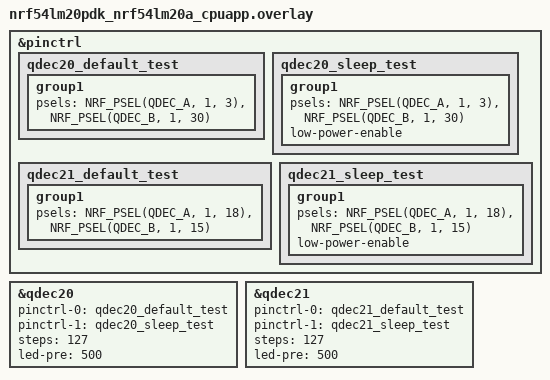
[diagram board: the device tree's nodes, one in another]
/*
 * Copyright (c) 2025 Nordic Semiconductor ASA
 *
 * SPDX-License-Identifier: LicenseRef-Nordic-5-Clause
 */

&pinctrl {
	qdec20_default_test: qdec20_default_test {
		group1 {
			psels = <NRF_PSEL(QDEC_A, 1, 3)>,
				<NRF_PSEL(QDEC_B, 1, 30)>;
		};
	};

	qdec20_sleep_test: qdec20_sleep_test {
		group1 {
			psels = <NRF_PSEL(QDEC_A, 1, 3)>,
				<NRF_PSEL(QDEC_B, 1, 30)>;
			low-power-enable;
		};
	};

	qdec21_default_test: qdec21_default_test {
		group1 {
			psels = <NRF_PSEL(QDEC_A, 1, 18)>,
				<NRF_PSEL(QDEC_B, 1, 15)>;
		};
	};

	qdec21_sleep_test: qdec21_sleep_test {
		group1 {
			psels = <NRF_PSEL(QDEC_A, 1, 18)>,
				<NRF_PSEL(QDEC_B, 1, 15)>;
			low-power-enable;
		};
	};
};

&qdec20 {
	status = "okay";
	pinctrl-0 = <&qdec20_default_test>;
	pinctrl-1 = <&qdec20_sleep_test>;
	pinctrl-names = "default", "sleep";
	steps = <127>;
	led-pre = <500>;
};

&qdec21 {
	status = "okay";
	pinctrl-0 = <&qdec21_default_test>;
	pinctrl-1 = <&qdec21_sleep_test>;
	pinctrl-names = "default", "sleep";
	steps = <127>;
	led-pre = <500>;
};
